# LRFDPBE register map
Vendor: Texas Instruments
Peripheral module from a debugger description file (folder CC27xxx10).
Registers are 32-bit, access per field, reset 0x0 unless marked. A register's access mark holds for its fields unless they carry their own. Offsets are as the file gives them; lines under a group give offsets from that group; [hi:lo] are bit positions; {n}, {i} and the like mark numbered series; 'fields as' and 'values as' point back to an identical list; <NAME> marks a mode.

## LRFDPBE
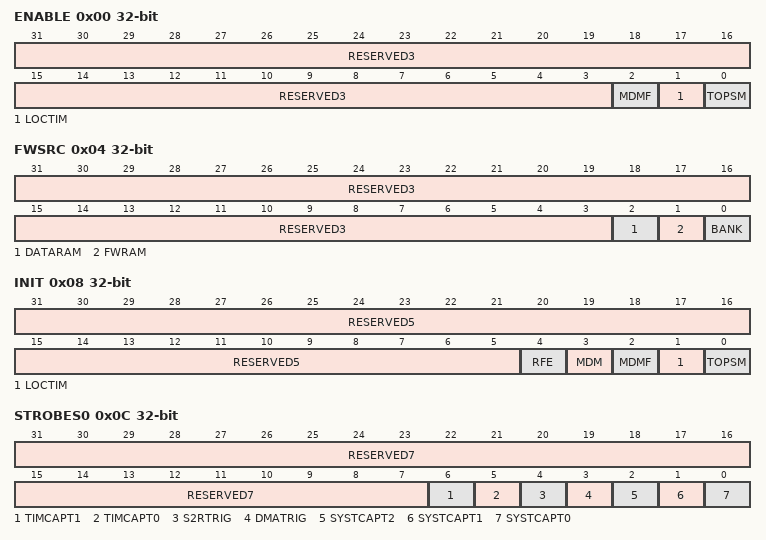
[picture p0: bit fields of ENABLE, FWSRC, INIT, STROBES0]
0x00 ENABLE — Internal. Only to be used through TI provided API.
  [31:3] RESERVED3 ro — Internal. Only to be used through TI provided API.
  [2] MDMF rw — Internal. Only to be used through TI provided API.
    1=EN (Internal. Only to be used through TI provided API.); 0=DIS (Internal. Only to be used through TI provided API.)
  [1] LOCTIM rw — Internal. Only to be used through TI provided API.
    values as MDMF
  [0] TOPSM rw — Internal. Only to be used through TI provided API.
    values as MDMF
0x04 FWSRC — Internal. Only to be used through TI provided API.
  [31:3] RESERVED3 ro — Internal. Only to be used through TI provided API.
  [2] DATARAM rw — Internal. Only to be used through TI provided API.
    1=S2RRAM (Internal. Only to be used through TI provided API.); 0=PBERAM (Internal. Only to be used through TI provided API.)
  [1] FWRAM rw — Internal. Only to be used through TI provided API.
    values as DATARAM
  [0] BANK rw — Internal. Only to be used through TI provided API.
    1=ONE (Internal. Only to be used through TI provided API.); 0=ZERO (Internal. Only to be used through TI provided API.)
0x08 INIT — Internal. Only to be used through TI provided API.
  [31:5] RESERVED5 ro — Internal. Only to be used through TI provided API.
  [4] RFE wo — Internal. Only to be used through TI provided API.
    1=RESET (Internal. Only to be used through TI provided API.); 0=NO_EFFECT (Internal. Only to be used through TI provided API.)
  [3] MDM wo — Internal. Only to be used through TI provided API.
    values as RFE
  [2] MDMF wo — Internal. Only to be used through TI provided API.
    values as RFE
  [1] LOCTIM wo — Internal. Only to be used through TI provided API.
    values as RFE
  [0] TOPSM wo — Internal. Only to be used through TI provided API.
    values as RFE
0x0C STROBES0 — Internal. Only to be used through TI provided API.
  [31:7] RESERVED7 ro — Internal. Only to be used through TI provided API.
  [6] TIMCAPT1 wo — Internal. Only to be used through TI provided API.
    values as FWSRC.BANK
  [5] TIMCAPT0 wo — Internal. Only to be used through TI provided API.
    values as FWSRC.BANK
  [4] S2RTRIG wo — Internal. Only to be used through TI provided API.
    1=ARM (Internal. Only to be used through TI provided API.); 0=NO_EFFECT (Internal. Only to be used through TI provided API.)
  [3] DMATRIG wo — Internal. Only to be used through TI provided API.
    values as S2RTRIG
  [2] SYSTCAPT2 wo — Internal. Only to be used through TI provided API.
    values as FWSRC.BANK
  [1] SYSTCAPT1 wo — Internal. Only to be used through TI provided API.
    values as FWSRC.BANK
  [0] SYSTCAPT0 wo — Internal. Only to be used through TI provided API.
    values as FWSRC.BANK
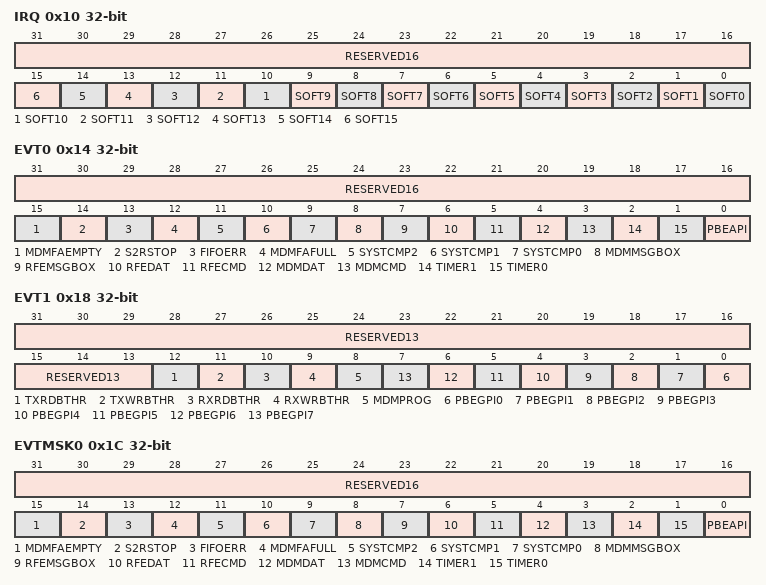
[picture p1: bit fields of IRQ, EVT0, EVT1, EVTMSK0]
0x10 IRQ — Internal. Only to be used through TI provided API.
  [31:16] RESERVED16 ro — Internal. Only to be used through TI provided API.
  [n] SOFT{n} wo (n=0..15) — Internal. Only to be used through TI provided API.
    1=ON (Internal. Only to be used through TI provided API.); 0=OFF (Internal. Only to be used through TI provided API.)
0x14 EVT0 ro — Internal. Only to be used through TI provided API.
  [31:16] RESERVED16 — Internal. Only to be used through TI provided API.
  [15] MDMFAEMPTY — Internal. Only to be used through TI provided API.
    values as FWSRC.BANK
  [14] S2RSTOP — Internal. Only to be used through TI provided API.
    values as FWSRC.BANK
  [13] FIFOERR — Internal. Only to be used through TI provided API.
    values as FWSRC.BANK
  [12] MDMFAFULL — Internal. Only to be used through TI provided API.
    values as FWSRC.BANK
  [11] SYSTCMP2 — Internal. Only to be used through TI provided API.
    values as FWSRC.BANK
  [10] SYSTCMP1 — Internal. Only to be used through TI provided API.
    values as FWSRC.BANK
  [9] SYSTCMP0 — Internal. Only to be used through TI provided API.
    values as FWSRC.BANK
  [8] MDMMSGBOX — Internal. Only to be used through TI provided API.
    values as FWSRC.BANK
  [7] RFEMSGBOX — Internal. Only to be used through TI provided API.
    values as FWSRC.BANK
  [6] RFEDAT — Internal. Only to be used through TI provided API.
    values as FWSRC.BANK
  [5] RFECMD — Internal. Only to be used through TI provided API.
    values as FWSRC.BANK
  [4] MDMDAT — Internal. Only to be used through TI provided API.
    values as FWSRC.BANK
  [3] MDMCMD — Internal. Only to be used through TI provided API.
    values as FWSRC.BANK
  [2] TIMER1 — Internal. Only to be used through TI provided API.
    values as FWSRC.BANK
  [1] TIMER0 — Internal. Only to be used through TI provided API.
    values as FWSRC.BANK
  [0] PBEAPI — Internal. Only to be used through TI provided API.
    values as FWSRC.BANK
0x18 EVT1 ro — Internal. Only to be used through TI provided API.
  [31:13] RESERVED13 — Internal. Only to be used through TI provided API.
  [12] TXRDBTHR — Internal. Only to be used through TI provided API.
    1=MET (Internal. Only to be used through TI provided API.); 0=BELOW (Internal. Only to be used through TI provided API.)
  [11] TXWRBTHR — Internal. Only to be used through TI provided API.
    values as TXRDBTHR
  [10] RXRDBTHR — Internal. Only to be used through TI provided API.
    values as TXRDBTHR
  [9] RXWRBTHR — Internal. Only to be used through TI provided API.
    values as TXRDBTHR
  [8] MDMPROG — Internal. Only to be used through TI provided API.
    values as FWSRC.BANK
  [n] PBEGPI{n} (n=0..7) — Internal. Only to be used through TI provided API.
    values as FWSRC.BANK
0x1C EVTMSK0 — Internal. Only to be used through TI provided API.
  [31:16] RESERVED16 ro — Internal. Only to be used through TI provided API.
  [15] MDMFAEMPTY rw — Internal. Only to be used through TI provided API.
    values as ENABLE.MDMF
  [14] S2RSTOP rw — Internal. Only to be used through TI provided API.
    values as ENABLE.MDMF
  [13] FIFOERR rw — Internal. Only to be used through TI provided API.
    values as ENABLE.MDMF
  [12] MDMFAFULL rw — Internal. Only to be used through TI provided API.
    values as ENABLE.MDMF
  [11] SYSTCMP2 rw — Internal. Only to be used through TI provided API.
    values as ENABLE.MDMF
  [10] SYSTCMP1 rw — Internal. Only to be used through TI provided API.
    values as ENABLE.MDMF
  [9] SYSTCMP0 rw — Internal. Only to be used through TI provided API.
    values as ENABLE.MDMF
  [8] MDMMSGBOX rw — Internal. Only to be used through TI provided API.
    values as ENABLE.MDMF
  [7] RFEMSGBOX rw — Internal. Only to be used through TI provided API.
    values as ENABLE.MDMF
  [6] RFEDAT rw — Internal. Only to be used through TI provided API.
    values as ENABLE.MDMF
  [5] RFECMD rw — Internal. Only to be used through TI provided API.
    values as ENABLE.MDMF
  [4] MDMDAT rw — Internal. Only to be used through TI provided API.
    values as ENABLE.MDMF
  [3] MDMCMD rw — Internal. Only to be used through TI provided API.
    values as ENABLE.MDMF
  [2] TIMER1 rw — Internal. Only to be used through TI provided API.
    values as ENABLE.MDMF
  [1] TIMER0 rw — Internal. Only to be used through TI provided API.
    values as ENABLE.MDMF
  [0] PBEAPI rw — Internal. Only to be used through TI provided API.
    values as ENABLE.MDMF
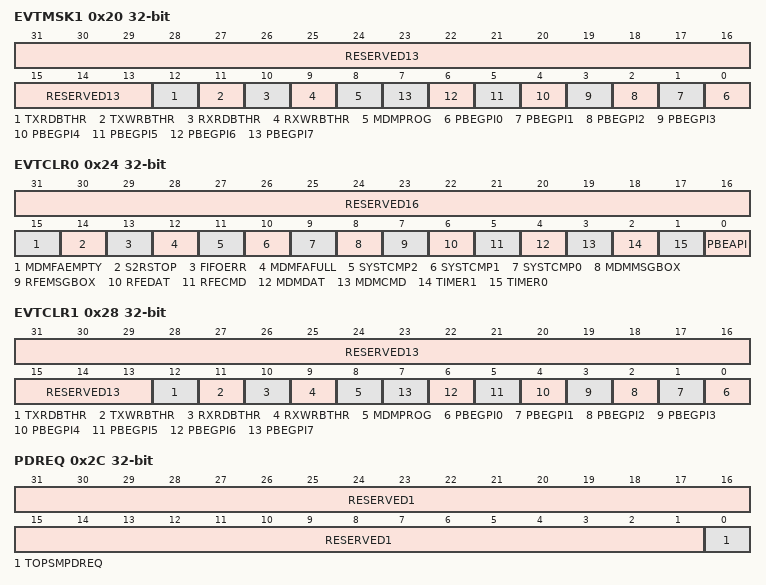
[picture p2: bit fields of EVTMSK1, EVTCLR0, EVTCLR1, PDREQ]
0x20 EVTMSK1 — Internal. Only to be used through TI provided API.
  [31:13] RESERVED13 ro — Internal. Only to be used through TI provided API.
  [12] TXRDBTHR rw — Internal. Only to be used through TI provided API.
    values as ENABLE.MDMF
  [11] TXWRBTHR rw — Internal. Only to be used through TI provided API.
    values as ENABLE.MDMF
  [10] RXRDBTHR rw — Internal. Only to be used through TI provided API.
    values as ENABLE.MDMF
  [9] RXWRBTHR rw — Internal. Only to be used through TI provided API.
    values as ENABLE.MDMF
  [8] MDMPROG rw — Internal. Only to be used through TI provided API.
    values as ENABLE.MDMF
  [n] PBEGPI{n} rw (n=0..7) — Internal. Only to be used through TI provided API.
    values as ENABLE.MDMF
0x24 EVTCLR0 — Internal. Only to be used through TI provided API.
  [31:16] RESERVED16 ro — Internal. Only to be used through TI provided API.
  [15] MDMFAEMPTY wo — Internal. Only to be used through TI provided API.
    1=CLEAR (Internal. Only to be used through TI provided API.); 0=RETAIN (Internal. Only to be used through TI provided API.)
  [14] S2RSTOP wo — Internal. Only to be used through TI provided API.
    values as MDMFAEMPTY
  [13] FIFOERR wo — Internal. Only to be used through TI provided API.
    values as MDMFAEMPTY
  [12] MDMFAFULL wo — Internal. Only to be used through TI provided API.
    values as MDMFAEMPTY
  [11] SYSTCMP2 wo — Internal. Only to be used through TI provided API.
    values as MDMFAEMPTY
  [10] SYSTCMP1 wo — Internal. Only to be used through TI provided API.
    values as MDMFAEMPTY
  [9] SYSTCMP0 wo — Internal. Only to be used through TI provided API.
    values as MDMFAEMPTY
  [8] MDMMSGBOX wo — Internal. Only to be used through TI provided API.
    values as MDMFAEMPTY
  [7] RFEMSGBOX wo — Internal. Only to be used through TI provided API.
    values as MDMFAEMPTY
  [6] RFEDAT wo — Internal. Only to be used through TI provided API.
    values as MDMFAEMPTY
  [5] RFECMD wo — Internal. Only to be used through TI provided API.
    values as MDMFAEMPTY
  [4] MDMDAT wo — Internal. Only to be used through TI provided API.
    values as MDMFAEMPTY
  [3] MDMCMD wo — Internal. Only to be used through TI provided API.
    values as MDMFAEMPTY
  [2] TIMER1 wo — Internal. Only to be used through TI provided API.
    values as MDMFAEMPTY
  [1] TIMER0 wo — Internal. Only to be used through TI provided API.
    values as MDMFAEMPTY
  [0] PBEAPI wo — Internal. Only to be used through TI provided API.
    values as MDMFAEMPTY
0x28 EVTCLR1 — Internal. Only to be used through TI provided API.
  [31:13] RESERVED13 ro — Internal. Only to be used through TI provided API.
  [12] TXRDBTHR wo — Internal. Only to be used through TI provided API.
    values as EVTCLR0.MDMFAEMPTY
  [11] TXWRBTHR wo — Internal. Only to be used through TI provided API.
    values as EVTCLR0.MDMFAEMPTY
  [10] RXRDBTHR wo — Internal. Only to be used through TI provided API.
    values as EVTCLR0.MDMFAEMPTY
  [9] RXWRBTHR wo — Internal. Only to be used through TI provided API.
    values as EVTCLR0.MDMFAEMPTY
  [8] MDMPROG wo — Internal. Only to be used through TI provided API.
    values as EVTCLR0.MDMFAEMPTY
  [n] PBEGPI{n} wo (n=0..7) — Internal. Only to be used through TI provided API.
    values as EVTCLR0.MDMFAEMPTY
0x2C PDREQ — Internal. Only to be used through TI provided API.
  [31:1] RESERVED1 ro — Internal. Only to be used through TI provided API.
  [0] TOPSMPDREQ rw — Internal. Only to be used through TI provided API.
    values as IRQ.SOFT0
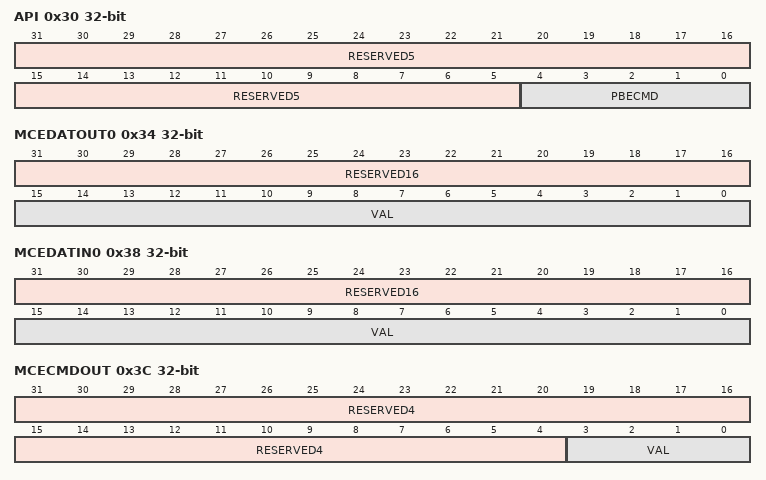
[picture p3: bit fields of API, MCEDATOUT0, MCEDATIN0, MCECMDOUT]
0x30 API — Internal. Only to be used through TI provided API.
  [31:5] RESERVED5 ro — Internal. Only to be used through TI provided API.
  [4:0] PBECMD rw — Internal. Only to be used through TI provided API.
    31=ALLONES (Internal. Only to be used through TI provided API.); 0=ALLZEROS (Internal. Only to be used through TI provided API.)
0x34 MCEDATOUT0 — Internal. Only to be used through TI provided API.
  [31:16] RESERVED16 ro — Internal. Only to be used through TI provided API.
  [15:0] VAL rw — Internal. Only to be used through TI provided API.
    0xFFFF=ALLONES (Internal. Only to be used through TI provided API.); 0=ALLZEROS (Internal. Only to be used through TI provided API.)
0x38 MCEDATIN0 ro — Internal. Only to be used through TI provided API.
  [31:16] RESERVED16 — Internal. Only to be used through TI provided API.
  [15:0] VAL — Internal. Only to be used through TI provided API.
    values as MCEDATOUT0.VAL
0x3C MCECMDOUT — Internal. Only to be used through TI provided API.
  [31:4] RESERVED4 ro — Internal. Only to be used through TI provided API.
  [3:0] VAL rw — Internal. Only to be used through TI provided API.
    15=ALLONES (Internal. Only to be used through TI provided API.); 0=ALLZEROS (Internal. Only to be used through TI provided API.)
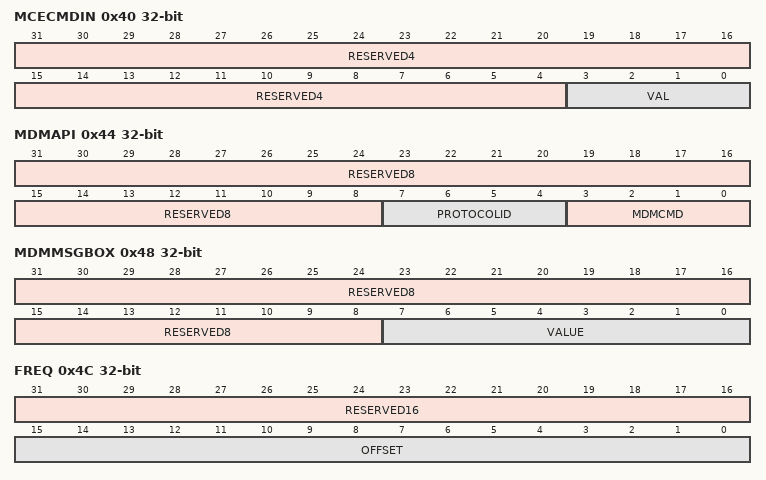
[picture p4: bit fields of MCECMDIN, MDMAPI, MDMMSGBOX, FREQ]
0x40 MCECMDIN ro — Internal. Only to be used through TI provided API.
  [31:4] RESERVED4 — Internal. Only to be used through TI provided API.
  [3:0] VAL — Internal. Only to be used through TI provided API.
    values as MCECMDOUT.VAL
0x44 MDMAPI — Internal. Only to be used through TI provided API.
  [31:8] RESERVED8 ro — Internal. Only to be used through TI provided API.
  [7:4] PROTOCOLID rw — Internal. Only to be used through TI provided API.
    values as MCECMDOUT.VAL
  [3:0] MDMCMD rw — Internal. Only to be used through TI provided API.
    values as MCECMDOUT.VAL
0x48 MDMMSGBOX ro — Internal. Only to be used through TI provided API.
  [31:8] RESERVED8 — Internal. Only to be used through TI provided API.
  [7:0] VALUE — Internal. Only to be used through TI provided API.
    255=ALLONES (Internal. Only to be used through TI provided API.); 0=ALLZEROS (Internal. Only to be used through TI provided API.)
0x4C FREQ ro — Internal. Only to be used through TI provided API.
  [31:16] RESERVED16 — Internal. Only to be used through TI provided API.
  [15:0] OFFSET — Internal. Only to be used through TI provided API.
    values as MCEDATOUT0.VAL
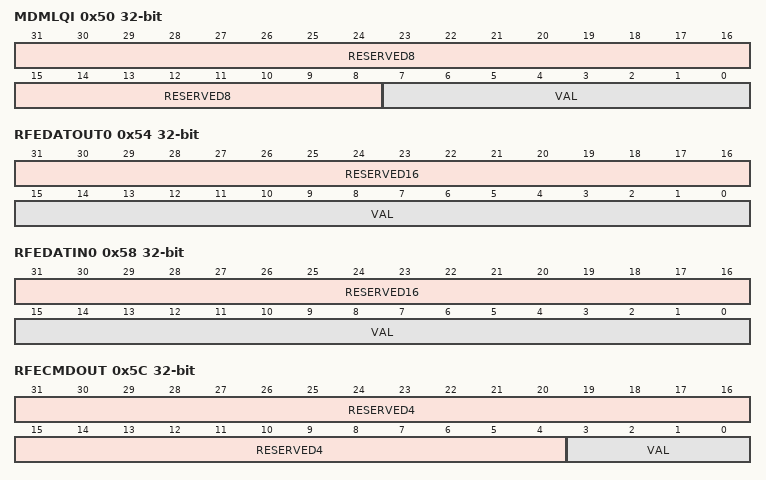
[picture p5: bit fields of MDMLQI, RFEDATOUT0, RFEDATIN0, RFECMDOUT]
0x50 MDMLQI ro — Internal. Only to be used through TI provided API.
  [31:8] RESERVED8 — Internal. Only to be used through TI provided API.
  [7:0] VAL — Internal. Only to be used through TI provided API.
    values as MDMMSGBOX.VALUE
0x54 RFEDATOUT0 — Internal. Only to be used through TI provided API.
  fields as MCEDATOUT0
0x58 RFEDATIN0 ro — Internal. Only to be used through TI provided API.
  fields as MCEDATIN0
0x5C RFECMDOUT — Internal. Only to be used through TI provided API.
  fields as MCECMDOUT
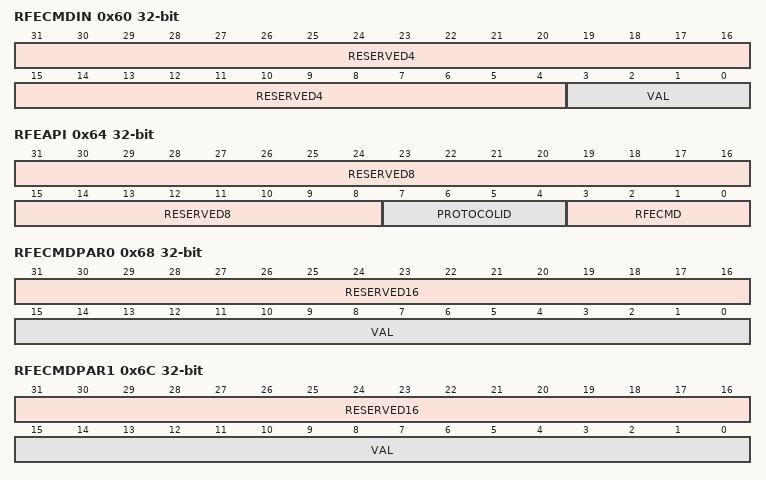
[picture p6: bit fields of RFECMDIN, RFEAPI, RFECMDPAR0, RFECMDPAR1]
0x60 RFECMDIN ro — Internal. Only to be used through TI provided API.
  fields as MCECMDIN
0x64 RFEAPI — Internal. Only to be used through TI provided API.
  [31:8] RESERVED8 ro — Internal. Only to be used through TI provided API.
  [7:4] PROTOCOLID rw — Internal. Only to be used through TI provided API.
    values as MCECMDOUT.VAL
  [3:0] RFECMD rw — Internal. Only to be used through TI provided API.
    values as MCECMDOUT.VAL
0x68 RFECMDPAR0 — Internal. Only to be used through TI provided API.
  fields as MCEDATOUT0
0x6C RFECMDPAR1 — Internal. Only to be used through TI provided API.
  fields as MCEDATOUT0
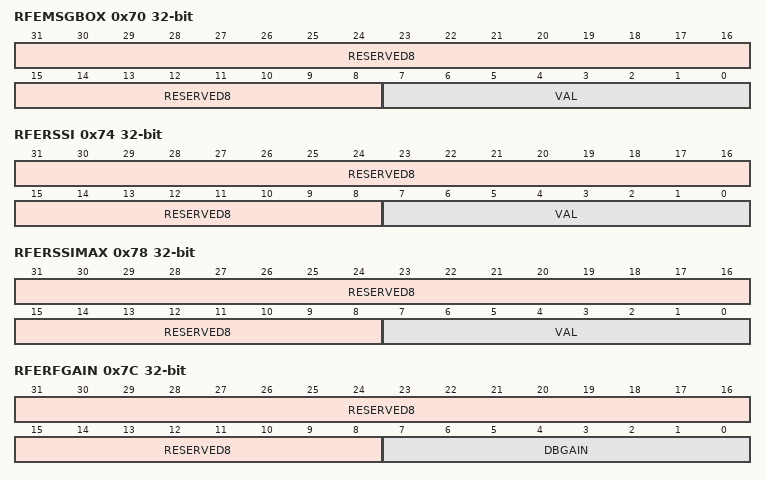
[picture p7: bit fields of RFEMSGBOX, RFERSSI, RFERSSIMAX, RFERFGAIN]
0x70 RFEMSGBOX ro — Internal. Only to be used through TI provided API.
  fields as MDMLQI
0x74 RFERSSI ro — Internal. Only to be used through TI provided API.
  fields as MDMLQI
0x78 RFERSSIMAX ro — Internal. Only to be used through TI provided API.
  fields as MDMLQI
0x7C RFERFGAIN ro — Internal. Only to be used through TI provided API.
  [31:8] RESERVED8 — Internal. Only to be used through TI provided API.
  [7:0] DBGAIN — Internal. Only to be used through TI provided API.
    values as MDMMSGBOX.VALUE
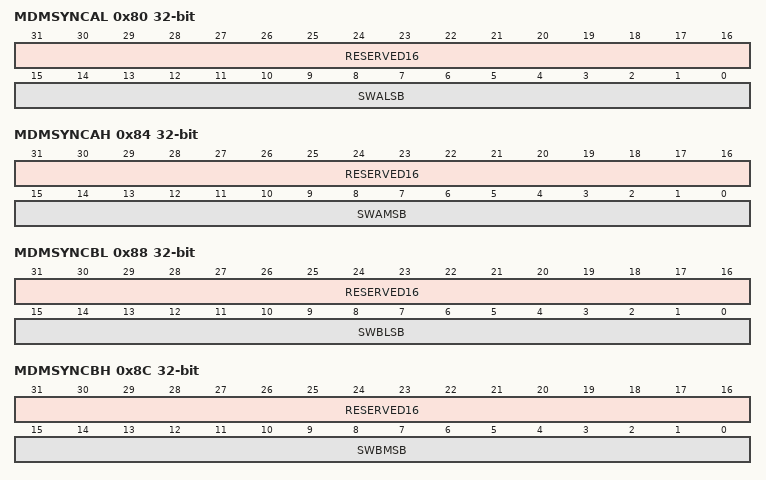
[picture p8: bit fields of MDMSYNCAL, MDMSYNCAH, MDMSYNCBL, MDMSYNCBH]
0x80 MDMSYNCAL — Internal. Only to be used through TI provided API.
  [31:16] RESERVED16 ro — Internal. Only to be used through TI provided API.
  [15:0] SWALSB rw — Internal. Only to be used through TI provided API.
    values as MCEDATOUT0.VAL
0x84 MDMSYNCAH — Internal. Only to be used through TI provided API.
  [31:16] RESERVED16 ro — Internal. Only to be used through TI provided API.
  [15:0] SWAMSB rw — Internal. Only to be used through TI provided API.
    values as MCEDATOUT0.VAL
0x88 MDMSYNCBL — Internal. Only to be used through TI provided API.
  [31:16] RESERVED16 ro — Internal. Only to be used through TI provided API.
  [15:0] SWBLSB rw — Internal. Only to be used through TI provided API.
    values as MCEDATOUT0.VAL
0x8C MDMSYNCBH — Internal. Only to be used through TI provided API.
  [31:16] RESERVED16 ro — Internal. Only to be used through TI provided API.
  [15:0] SWBMSB rw — Internal. Only to be used through TI provided API.
    values as MCEDATOUT0.VAL
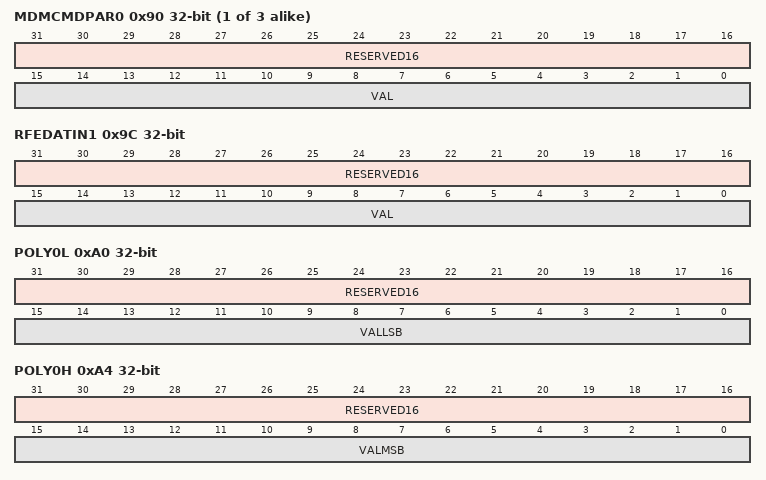
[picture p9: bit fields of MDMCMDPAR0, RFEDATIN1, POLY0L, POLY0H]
{0x90+4i} MDMCMDPAR{i} (i=0..2) — Internal. Only to be used through TI provided API.
  fields as MCEDATOUT0
0x9C RFEDATIN1 ro — Internal. Only to be used through TI provided API.
  fields as MCEDATIN0
0xA0 POLY0L — Internal. Only to be used through TI provided API.
  [31:16] RESERVED16 ro — Internal. Only to be used through TI provided API.
  [15:0] VALLSB rw — Internal. Only to be used through TI provided API.
    values as MCEDATOUT0.VAL
0xA4 POLY0H — Internal. Only to be used through TI provided API.
  [31:16] RESERVED16 ro — Internal. Only to be used through TI provided API.
  [15:0] VALMSB rw — Internal. Only to be used through TI provided API.
    values as MCEDATOUT0.VAL
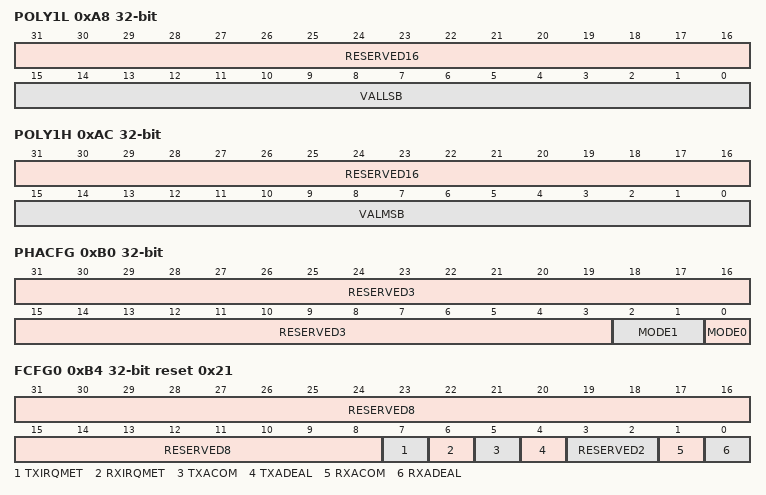
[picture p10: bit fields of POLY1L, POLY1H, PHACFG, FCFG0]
0xA8 POLY1L — Internal. Only to be used through TI provided API.
  fields as POLY0L
0xAC POLY1H — Internal. Only to be used through TI provided API.
  fields as POLY0H
0xB0 PHACFG — Internal. Only to be used through TI provided API.
  [31:3] RESERVED3 ro — Internal. Only to be used through TI provided API.
  [2:1] MODE1 rw — Internal. Only to be used through TI provided API.
    2=PARAL (Internal. Only to be used through TI provided API.); 1=CASC (Internal. Only to be used through TI provided API.); 0=INDEP (Internal. Only to be used through TI provided API.)
  [0] MODE0 rw — Internal. Only to be used through TI provided API.
    1=WHITE (Internal. Only to be used through TI provided API.); 0=CRC (Internal. Only to be used through TI provided API.)
0xB4 FCFG0 reset 0x21 — Internal. Only to be used through TI provided API.
  [31:8] RESERVED8 ro — Internal. Only to be used through TI provided API.
  [7] TXIRQMET rw — Internal. Only to be used through TI provided API.
    1=TXRDBTHR (Internal. Only to be used through TI provided API.); 0=TXWRBTHR (Internal. Only to be used through TI provided API.)
  [6] RXIRQMET rw — Internal. Only to be used through TI provided API.
    1=RXWRBTHR (Internal. Only to be used through TI provided API.); 0=RXRDBTHR (Internal. Only to be used through TI provided API.)
  [5] TXACOM rw — Internal. Only to be used through TI provided API.
    values as ENABLE.MDMF
  [4] TXADEAL rw — Internal. Only to be used through TI provided API.
    values as ENABLE.MDMF
  [3:2] RESERVED2 ro — Internal. Only to be used through TI provided API.
  [1] RXACOM rw — Internal. Only to be used through TI provided API.
    values as ENABLE.MDMF
  [0] RXADEAL rw — Internal. Only to be used through TI provided API.
    values as ENABLE.MDMF
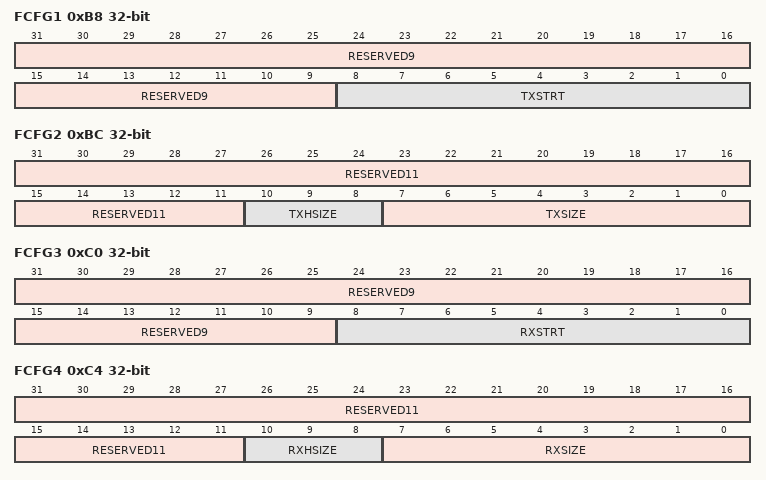
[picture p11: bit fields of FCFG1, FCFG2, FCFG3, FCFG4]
0xB8 FCFG1 — Internal. Only to be used through TI provided API.
  [31:9] RESERVED9 ro — Internal. Only to be used through TI provided API.
  [8:0] TXSTRT rw — Internal. Only to be used through TI provided API.
    0x1FF=ONES (Internal. Only to be used through TI provided API.); 0=ZEROS (Internal. Only to be used through TI provided API.)
0xBC FCFG2 — Internal. Only to be used through TI provided API.
  [31:11] RESERVED11 ro — Internal. Only to be used through TI provided API.
  [10:8] TXHSIZE rw — Internal. Only to be used through TI provided API.
    2=WORD (Internal. Only to be used through TI provided API.); 1=HALFW (Internal. Only to be used through TI provided API.); 0=BYTE (Internal. Only to be used through TI provided API.)
  [7:0] TXSIZE rw — Internal. Only to be used through TI provided API.
    255=ONES (Internal. Only to be used through TI provided API.); 0=ZEROS (Internal. Only to be used through TI provided API.)
0xC0 FCFG3 — Internal. Only to be used through TI provided API.
  [31:9] RESERVED9 ro — Internal. Only to be used through TI provided API.
  [8:0] RXSTRT rw — Internal. Only to be used through TI provided API.
    values as FCFG1.TXSTRT
0xC4 FCFG4 — Internal. Only to be used through TI provided API.
  [31:11] RESERVED11 ro — Internal. Only to be used through TI provided API.
  [10:8] RXHSIZE rw — Internal. Only to be used through TI provided API.
    values as FCFG2.TXHSIZE
  [7:0] RXSIZE rw — Internal. Only to be used through TI provided API.
    values as FCFG2.TXSIZE
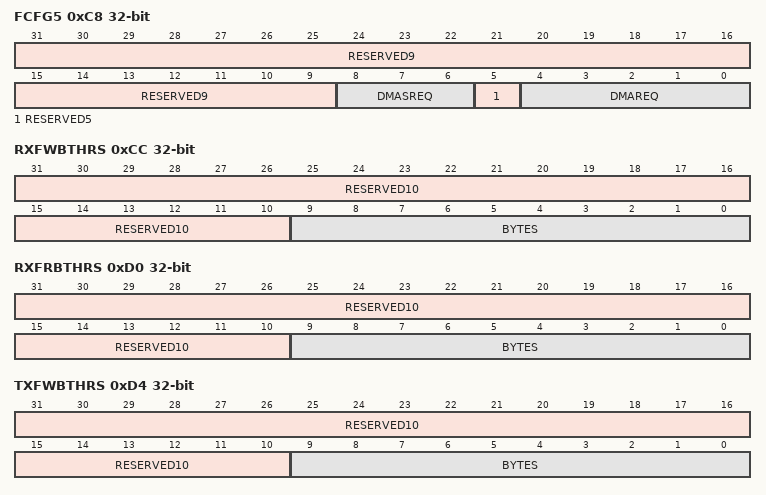
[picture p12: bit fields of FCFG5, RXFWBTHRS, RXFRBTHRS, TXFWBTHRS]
0xC8 FCFG5 — Internal. Only to be used through TI provided API.
  [31:9] RESERVED9 ro — Internal. Only to be used through TI provided API.
  [8:6] DMASREQ rw — Internal. Only to be used through TI provided API.
    4=TXFIFOFREE (Internal. Only to be used through TI provided API.); 3=TXFIFOMD (Internal. Only to be used through TI provided API.); 2=RXFIFOFREE (Internal. Only to be used through TI provided API.); 1=RXFIFOMD (Internal. Only to be used through TI provided API.); 0=NONE (Internal. Only to be used through TI provided API.)
  [5] RESERVED5 ro — Internal. Only to be used through TI provided API.
  [4:0] DMAREQ rw — Internal. Only to be used through TI provided API.
    15=TXFIFO_COMMIT (Internal. Only to be used through TI provided API.); 14=TXFIFO_DISCARD (Internal. Only to be used through TI provided API.); 13=TXFIFO_RETRY (Internal. Only to be used through TI provided API.); 12=TXFIFO_DEALLOC (Internal. Only to be used through TI provided API.); 11=TXFIFO_RESET (Internal. Only to be used through TI provided API.); 10=TXWRBTHR_MET (Internal. Only to be used through TI provided API.); 9=TXRDBTHR_MET (Internal. Only to be used through TI provided API.); 7=RXFIFO_COMMIT (Internal. Only to be used through TI provided API.); 6=RXFIFO_DISCARD (Internal. Only to be used through TI provided API.); 5=RXFIFO_RETRY (Internal. Only to be used through TI provided API.); 4=RXFIFO_DEALLOC (Internal. Only to be used through TI provided API.); 3=RXFIFO_RESET (Internal. Only to be used through TI provided API.); 2=RXWRBTHR_MET (Internal. Only to be used through TI provided API.); 1=RXRDBTHR_MET (Internal. Only to be used through TI provided API.); 0=NONE (Internal. Only to be used through TI provided API.)
0xCC RXFWBTHRS — Internal. Only to be used through TI provided API.
  [31:10] RESERVED10 ro — Internal. Only to be used through TI provided API.
  [9:0] BYTES rw — Internal. Only to be used through TI provided API.
    0x3FF=ALLONES (Internal. Only to be used through TI provided API.); 0=ALLZEROS (Internal. Only to be used through TI provided API.)
0xD0 RXFRBTHRS — Internal. Only to be used through TI provided API.
  fields as RXFWBTHRS
0xD4 TXFWBTHRS — Internal. Only to be used through TI provided API.
  fields as RXFWBTHRS
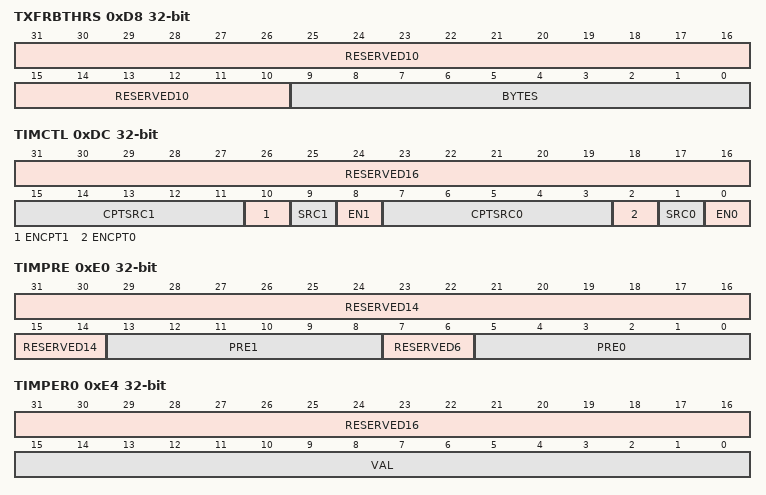
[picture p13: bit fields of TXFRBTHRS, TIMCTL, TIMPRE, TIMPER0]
0xD8 TXFRBTHRS — Internal. Only to be used through TI provided API.
  fields as RXFWBTHRS
0xDC TIMCTL — Internal. Only to be used through TI provided API.
  [31:16] RESERVED16 ro — Internal. Only to be used through TI provided API.
  [15:11] CPTSRC1 rw — Internal. Only to be used through TI provided API.
    values as API.PBECMD
  [10] ENCPT1 rw — Internal. Only to be used through TI provided API.
    values as IRQ.SOFT0
  [9] SRC1 rw — Internal. Only to be used through TI provided API.
    1=PRE1 (Internal. Only to be used through TI provided API.); 0=CLK (Internal. Only to be used through TI provided API.)
  [8] EN1 rw — Internal. Only to be used through TI provided API.
    values as IRQ.SOFT0
  [7:3] CPTSRC0 rw — Internal. Only to be used through TI provided API.
    values as API.PBECMD
  [2] ENCPT0 rw — Internal. Only to be used through TI provided API.
    values as IRQ.SOFT0
  [1] SRC0 rw — Internal. Only to be used through TI provided API.
    1=PRE0 (Internal. Only to be used through TI provided API.); 0=CLK (Internal. Only to be used through TI provided API.)
  [0] EN0 rw — Internal. Only to be used through TI provided API.
    values as IRQ.SOFT0
0xE0 TIMPRE — Internal. Only to be used through TI provided API.
  [31:14] RESERVED14 ro — Internal. Only to be used through TI provided API.
  [13:8] PRE1 rw — Internal. Only to be used through TI provided API.
    63=DIV64 (Internal. Only to be used through TI provided API.); 0=NO_DIV (Internal. Only to be used through TI provided API.)
  [7:6] RESERVED6 ro — Internal. Only to be used through TI provided API.
  [5:0] PRE0 rw — Internal. Only to be used through TI provided API.
    values as PRE1
0xE4 TIMPER0 — Internal. Only to be used through TI provided API.
  fields as MCEDATOUT0
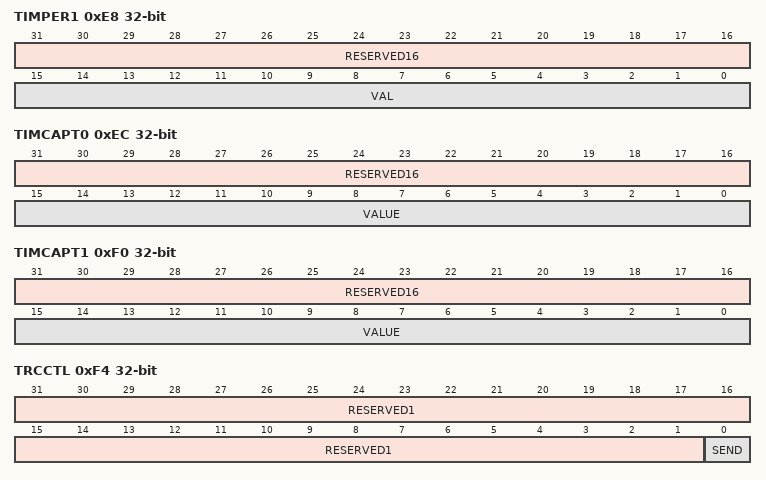
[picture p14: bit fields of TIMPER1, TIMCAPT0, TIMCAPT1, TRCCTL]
0xE8 TIMPER1 — Internal. Only to be used through TI provided API.
  fields as MCEDATOUT0
0xEC TIMCAPT0 ro — Internal. Only to be used through TI provided API.
  [31:16] RESERVED16 — Internal. Only to be used through TI provided API.
  [15:0] VALUE — Internal. Only to be used through TI provided API.
    values as MCEDATOUT0.VAL
0xF0 TIMCAPT1 ro — Internal. Only to be used through TI provided API.
  fields as TIMCAPT0
0xF4 TRCCTL — Internal. Only to be used through TI provided API.
  [31:1] RESERVED1 ro — Internal. Only to be used through TI provided API.
  [0] SEND wo — Internal. Only to be used through TI provided API.
    values as FWSRC.BANK
0xF8 TRCSTAT ro — Internal. Only to be used through TI provided API.
  [31:1] RESERVED1 — Internal. Only to be used through TI provided API.
  [0] BUSY — Internal. Only to be used through TI provided API.
    values as FWSRC.BANK
0xFC TRCCMD — Internal. Only to be used through TI provided API.
  [31:10] RESERVED10 ro — Internal. Only to be used through TI provided API.
  [9:8] PARCNT rw — Internal. Only to be used through TI provided API.
    3=ALLONES (Internal. Only to be used through TI provided API.); 0=ALLZEROS (Internal. Only to be used through TI provided API.)
  [7:0] PKTHDR rw — Internal. Only to be used through TI provided API.
    values as MDMMSGBOX.VALUE
0x100 TRCPAR0 — Internal. Only to be used through TI provided API.
  fields as MCEDATOUT0
0x104 TRCPAR1 — Internal. Only to be used through TI provided API.
  fields as MCEDATOUT0
0x108 GPOCTRL — Internal. Only to be used through TI provided API.
  [31:8] RESERVED8 ro — Internal. Only to be used through TI provided API.
  [n] GPO{n} rw (n=0..7) — Internal. Only to be used through TI provided API.
    values as FWSRC.BANK
0x10C MDMFWR — Internal. Only to be used through TI provided API.
  [31:16] RESERVED16 ro — Internal. Only to be used through TI provided API.
  [15:0] PAYLOADIN rw — Internal. Only to be used through TI provided API.
    values as MCEDATOUT0.VAL
0x110 MDMFRD ro — Internal. Only to be used through TI provided API.
  [31:16] RESERVED16 — Internal. Only to be used through TI provided API.
  [15:0] PAYLOADOUT — Internal. Only to be used through TI provided API.
    values as MCEDATOUT0.VAL
0x114 MDMFWRCTL — Internal. Only to be used through TI provided API.
  [31:4] RESERVED4 ro — Internal. Only to be used through TI provided API.
  [3:0] WORDSZWR rw — Internal. Only to be used through TI provided API.
    {v}=BITS{v+1} (Internal. Only to be used through TI provided API.) (v=0..15)
0x118 MDMFRDCTL — Internal. Only to be used through TI provided API.
  [31:4] RESERVED4 ro — Internal. Only to be used through TI provided API.
  [3:0] WORDSZRD rw — Internal. Only to be used through TI provided API.
    values as MDMFWRCTL.WORDSZWR
0x11C MDMFCFG — Internal. Only to be used through TI provided API.
  [31:16] RESERVED16 ro — Internal. Only to be used through TI provided API.
  [15:8] AFULLTHR rw — Internal. Only to be used through TI provided API.
    values as MDMMSGBOX.VALUE
  [7:0] AEMPTYTHR rw — Internal. Only to be used through TI provided API.
    values as MDMMSGBOX.VALUE
0x120 MDMFSTA ro — Internal. Only to be used through TI provided API.
  [31:6] RESERVED6 — Internal. Only to be used through TI provided API.
  [5] OVFL — Internal. Only to be used through TI provided API.
    values as FWSRC.BANK
  [4] ALMOSTFULL — Internal. Only to be used through TI provided API.
    values as FWSRC.BANK
  [3] ALMOSTEMPTY — Internal. Only to be used through TI provided API.
    values as FWSRC.BANK
  [2] UNFL — Internal. Only to be used through TI provided API.
    values as FWSRC.BANK
  [1] RXVALID — Internal. Only to be used through TI provided API.
    values as FWSRC.BANK
  [0] TXREADY — Internal. Only to be used through TI provided API.
    values as FWSRC.BANK
0x124 PHASTA ro — Internal. Only to be used through TI provided API.
  [31:2] RESERVED2 — Internal. Only to be used through TI provided API.
  [1:0] BUSY — Internal. Only to be used through TI provided API.
    1=BUSY (Internal. Only to be used through TI provided API.); 0=IDLE (Internal. Only to be used through TI provided API.)
0x128 LFSR0L reset 0xFFFF — Internal. Only to be used through TI provided API.
  fields as POLY0L
0x12C LFSR0H reset 0xFFFF — Internal. Only to be used through TI provided API.
  fields as POLY0H
0x130 LFSR0BRL reset 0xFFFF — Internal. Only to be used through TI provided API.
  fields as POLY0L
0x134 LFSR0BRH reset 0xFFFF — Internal. Only to be used through TI provided API.
  fields as POLY0H
0x138 LFSR1L reset 0xFFFF — Internal. Only to be used through TI provided API.
  fields as POLY0L
0x13C LFSR1H reset 0xFFFF — Internal. Only to be used through TI provided API.
  fields as POLY0H
0x140 LFSR1BRL reset 0xFFFF — Internal. Only to be used through TI provided API.
  fields as POLY0L
0x144 LFSR1BRH reset 0xFFFF — Internal. Only to be used through TI provided API.
  fields as POLY0H
0x148 LFSR0INL — Internal. Only to be used through TI provided API.
  [31:16] RESERVED16 ro — Internal. Only to be used through TI provided API.
  [15:0] VAL wo — Internal. Only to be used through TI provided API.
    values as TRCCMD.PARCNT
0x14C LFSR0N — Internal. Only to be used through TI provided API.
  [31:4] RESERVED4 ro — Internal. Only to be used through TI provided API.
  [3:0] SIZE rw — Internal. Only to be used through TI provided API.
    values as MCECMDOUT.VAL
0x150 LFSR0INM — Internal. Only to be used through TI provided API.
  [31:16] RESERVED16 ro — Internal. Only to be used through TI provided API.
  [15:0] VAL wo — Internal. Only to be used through TI provided API.
    values as FWSRC.BANK
0x154 PHAOUT0 — Internal. Only to be used through TI provided API.
  [31:16] RESERVED16 ro — Internal. Only to be used through TI provided API.
  [15:0] VAL rw — Internal. Only to be used through TI provided API.
    0xDCD7=ALLONES (Internal. Only to be used through TI provided API.); 0=ALLZEROS (Internal. Only to be used through TI provided API.)
0x158 LFSR1INL — Internal. Only to be used through TI provided API.
  fields as LFSR0INL
0x15C LFSR1N — Internal. Only to be used through TI provided API.
  fields as LFSR0N
0x160 LFSR1INM — Internal. Only to be used through TI provided API.
  fields as LFSR0INM
0x164 PHAOUT0BR ro — Internal. Only to be used through TI provided API.
  fields as MCEDATIN0
0x168 DIVIDENDL — Internal. Only to be used through TI provided API.
  [31:16] RESERVED16 ro — Internal. Only to be used through TI provided API.
  [15:0] VALLSB wo — Internal. Only to be used through TI provided API.
    values as MCEDATOUT0.VAL
0x16C DIVIDENDH — Internal. Only to be used through TI provided API.
  [31:16] RESERVED16 ro — Internal. Only to be used through TI provided API.
  [15:0] VALMSB wo — Internal. Only to be used through TI provided API.
    values as MCEDATOUT0.VAL
0x170 DIVISORL — Internal. Only to be used through TI provided API.
  fields as POLY0L
0x174 DIVISORH — Internal. Only to be used through TI provided API.
  fields as POLY0H
0x178 QUOTIENTL ro — Internal. Only to be used through TI provided API.
  [31:16] RESERVED16 — Internal. Only to be used through TI provided API.
  [15:0] VALLSB — Internal. Only to be used through TI provided API.
    values as MCEDATOUT0.VAL
0x17C QUOTIENTH ro — Internal. Only to be used through TI provided API.
  [31:16] RESERVED16 — Internal. Only to be used through TI provided API.
  [15:0] VALMSB — Internal. Only to be used through TI provided API.
    values as MCEDATOUT0.VAL
{0x180+8i} SYSTIM{i}L ro (i=0..2) — Internal. Only to be used through TI provided API.
  [31:16] RESERVED16 — Internal. Only to be used through TI provided API.
  [15:0] VALLSB — Internal. Only to be used through TI provided API.
    values as FWSRC.BANK
{0x184+8i} SYSTIM{i}H ro (i=0..2) — Internal. Only to be used through TI provided API.
  [31:16] RESERVED16 — Internal. Only to be used through TI provided API.
  [15:0] VALMSB — Internal. Only to be used through TI provided API.
    values as FWSRC.BANK
0x198 GPI ro — Internal. Only to be used through TI provided API.
  [31:8] RESERVED8 — Internal. Only to be used through TI provided API.
  [n] GPI{n} (n=0..7) — Internal. Only to be used through TI provided API.
    values as FWSRC.BANK
0x19C DIVSTA ro — Internal. Only to be used through TI provided API.
  [31:1] RESERVED1 — Internal. Only to be used through TI provided API.
  [0] STAT — Internal. Only to be used through TI provided API.
    values as PHASTA.BUSY
0x1A0 FCMD — Internal. Only to be used through TI provided API.
  [31:8] RESERVED8 ro — Internal. Only to be used through TI provided API.
  [7:0] DATA wo — Internal. Only to be used through TI provided API.
    15=FIFO_COMMIT (Internal. Only to be used through TI provided API.); 14=FIFO_DISCARD (Internal. Only to be used through TI provided API.); 13=FIFO_RETRY (Internal. Only to be used through TI provided API.); 12=FIFO_DEALLOC (Internal. Only to be used through TI provided API.); 11=FIFO_RESET (Internal. Only to be used through TI provided API.); 10=RXFIFO_RETRY (Internal. Only to be used through TI provided API.); 9=RXFIFO_DISCARD (Internal. Only to be used through TI provided API.); 8=RXFIFO_COMMIT (Internal. Only to be used through TI provided API.); 7=TXFIFO_RESET (Internal. Only to be used through TI provided API.); 6=TXFIFO_DEALLOC (Internal. Only to be used through TI provided API.); 5=TXFIFO_RETRY (Internal. Only to be used through TI provided API.); 4=TXFIFO_DISCARD (Internal. Only to be used through TI provided API.); 3=TXFIFO_COMMIT (Internal. Only to be used through TI provided API.); 2=RXFIFO_DEALLOC (Internal. Only to be used through TI provided API.); 1=RXFIFO_RESET (Internal. Only to be used through TI provided API.)
0x1A4 FSTAT ro — Internal. Only to be used through TI provided API.
  [31:12] RESERVED12 — Internal. Only to be used through TI provided API.
  [11] TXUNFL — Internal. Only to be used through TI provided API.
    1=TRUE (Internal. Only to be used through TI provided API.); 0=FALSE (Internal. Only to be used through TI provided API.)
  [10] TXOVFL — Internal. Only to be used through TI provided API.
    values as TXUNFL
  [9] TXEMPTY — Internal. Only to be used through TI provided API.
    values as TXUNFL
  [8] TXFULL — Internal. Only to be used through TI provided API.
    values as TXUNFL
  [7:4] RESERVED4 — Internal. Only to be used through TI provided API.
  [3] RXUNFL — Internal. Only to be used through TI provided API.
    values as TXUNFL
  [2] RXOVFL — Internal. Only to be used through TI provided API.
    values as TXUNFL
  [1] RXEMPTY — Internal. Only to be used through TI provided API.
    values as TXUNFL
  [0] RXFULL — Internal. Only to be used through TI provided API.
    values as TXUNFL
0x1A8 RXFWP — Internal. Only to be used through TI provided API.
  [31:10] RESERVED10 ro — Internal. Only to be used through TI provided API.
  [9:0] PTR rw — Internal. Only to be used through TI provided API.
    values as RXFWBTHRS.BYTES
0x1AC RXFRP — Internal. Only to be used through TI provided API.
  fields as RXFWP
0x1B0 RXFSWP — Internal. Only to be used through TI provided API.
  fields as RXFWP
0x1B4 RXFSRP — Internal. Only to be used through TI provided API.
  fields as RXFWP
0x1B8 TXFWP — Internal. Only to be used through TI provided API.
  fields as RXFWP
0x1BC TXFRP — Internal. Only to be used through TI provided API.
  fields as RXFWP
0x1C0 TXFSWP — Internal. Only to be used through TI provided API.
  fields as RXFWP
0x1C4 TXFSRP — Internal. Only to be used through TI provided API.
  [31:10] RESERVED10 ro — Internal. Only to be used through TI provided API.
  [9:0] PTR rw — Internal. Only to be used through TI provided API.
    0x3FF=ALLONES_2 (Internal. Only to be used through TI provided API.); 0=ALLZEROS (Internal. Only to be used through TI provided API.)
0x1C8 RXFWRITABLE ro — Internal. Only to be used through TI provided API.
  [31:10] RESERVED10 — Internal. Only to be used through TI provided API.
  [9:0] BYTES — Internal. Only to be used through TI provided API.
    values as RXFWBTHRS.BYTES
0x1CC RXFREADABLE ro — Internal. Only to be used through TI provided API.
  fields as RXFWRITABLE
0x1D0 TXFWRITABLE ro — Internal. Only to be used through TI provided API.
  fields as RXFWRITABLE
0x1D4 TXFREADABLE ro — Internal. Only to be used through TI provided API.
  fields as RXFWRITABLE
0x1D8 RXFBRD ro — Internal. Only to be used through TI provided API.
  [31:8] RESERVED8 — Internal. Only to be used through TI provided API.
  [7:0] DATA — Internal. Only to be used through TI provided API.
    values as MDMMSGBOX.VALUE
0x1DC RXFBWR — Internal. Only to be used through TI provided API.
  [31:8] RESERVED8 ro — Internal. Only to be used through TI provided API.
  [7:0] DATA wo — Internal. Only to be used through TI provided API.
    values as MDMMSGBOX.VALUE
0x1E0 TXFBRD ro — Internal. Only to be used through TI provided API.
  fields as RXFBRD
0x1E4 TXFBWR — Internal. Only to be used through TI provided API.
  fields as RXFBWR
0x1E8 RXFHRD ro — Internal. Only to be used through TI provided API.
  [31:16] RESERVED16 — Internal. Only to be used through TI provided API.
  [15:0] DATA — Internal. Only to be used through TI provided API.
    values as MCEDATOUT0.VAL
0x1EC RXFHWR — Internal. Only to be used through TI provided API.
  [31:16] RESERVED16 ro — Internal. Only to be used through TI provided API.
  [15:0] DATA wo — Internal. Only to be used through TI provided API.
    values as MCEDATOUT0.VAL
0x1F0 TXFHRD ro — Internal. Only to be used through TI provided API.
  fields as RXFHRD
0x1F4 TXFHWR — Internal. Only to be used through TI provided API.
  fields as RXFHWR
0x1F8 MCEDATIN1 ro — Internal. Only to be used through TI provided API.
  fields as MCEDATIN0
